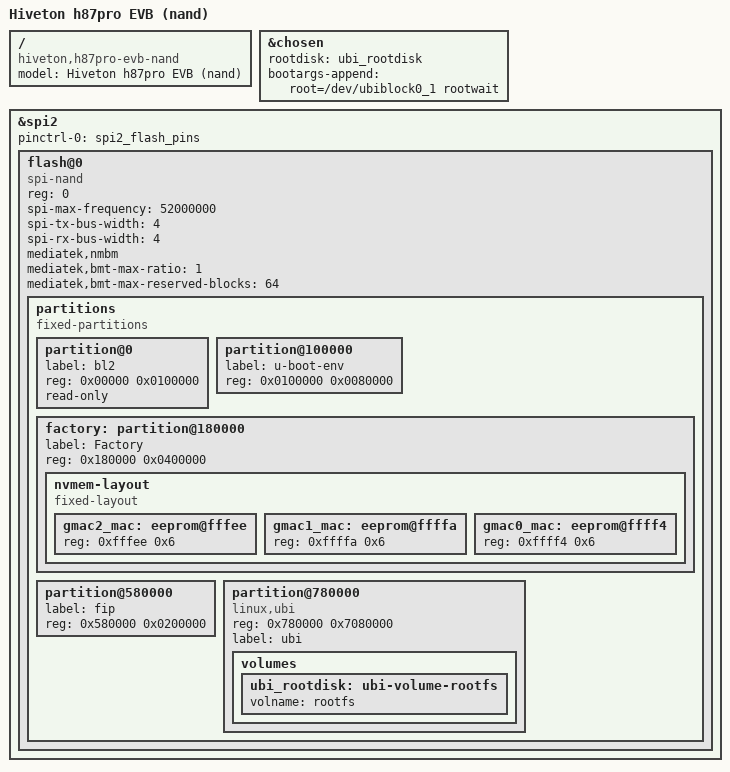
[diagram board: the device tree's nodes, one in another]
// SPDX-License-Identifier: (GPL-2.0 OR MIT)

/dts-v1/;
#include "mt7987a-hiveton-h87pro-evb-base.dts"

/ {
	model = "Hiveton h87pro EVB (nand)";
	compatible = "hiveton,h87pro-evb-nand", "mediatek,mt7987";
};

&chosen {
	rootdisk = <&ubi_rootdisk>;
	bootargs-append = " root=/dev/ubiblock0_1 rootwait";
};

&spi2 {
	pinctrl-names = "default";
	pinctrl-0 = <&spi2_flash_pins>;
	status = "okay";

	flash@0 {
		compatible = "spi-nand";
		#address-cells = <1>;
		#size-cells = <1>;
		reg = <0>;

		spi-max-frequency = <52000000>;
		spi-tx-bus-width = <4>;
		spi-rx-bus-width = <4>;

		mediatek,nmbm;
		mediatek,bmt-max-ratio = <1>;
		mediatek,bmt-max-reserved-blocks = <64>;

		partitions {
			compatible = "fixed-partitions";
			#address-cells = <1>;
			#size-cells = <1>;

			partition@0 {
				label = "bl2";
				reg = <0x00000 0x0100000>;
				read-only;
			};

			partition@100000 {
				label = "u-boot-env";
				reg = <0x0100000 0x0080000>;
			};

			factory: partition@180000 {
				label = "Factory";
				reg = <0x180000 0x0400000>;

				nvmem-layout {
					compatible = "fixed-layout";
					#address-cells = <1>;
					#size-cells = <1>;

					gmac2_mac: eeprom@fffee {
						reg = <0xfffee 0x6>;
					};

					gmac1_mac: eeprom@ffffa {
						reg = <0xffffa 0x6>;
					};

					gmac0_mac: eeprom@ffff4 {
						reg = <0xffff4 0x6>;
					};
				};
			};

			partition@580000 {
				label = "fip";
				reg = <0x580000 0x0200000>;
			};

			partition@780000 {
				compatible = "linux,ubi";
				reg = <0x780000 0x7080000>;
				label = "ubi";

				volumes {
					ubi_rootdisk: ubi-volume-rootfs {
						volname = "rootfs";
					};
				};
			};
		};
	};
};
